AUTOSAR XML (schema 00052)
package /apd/AdaptiveApplicationSwComponentTypes
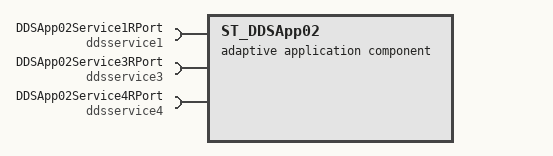
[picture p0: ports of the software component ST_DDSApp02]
  adaptive application sw component type ST_DDSApp02
    require port DDSApp02Service1RPort: required-interface=ddsservice1
    require port DDSApp02Service3RPort: required-interface=ddsservice3
    require port DDSApp02Service4RPort: required-interface=ddsservice4
package /apd/Executables
  executable ST_DDSApp02: category=APPLICATION_LEVEL, minimum-timer-granularity=1000
    root sw component prototype ST_DDSApp02Root: application-type=ST_DDSApp02
